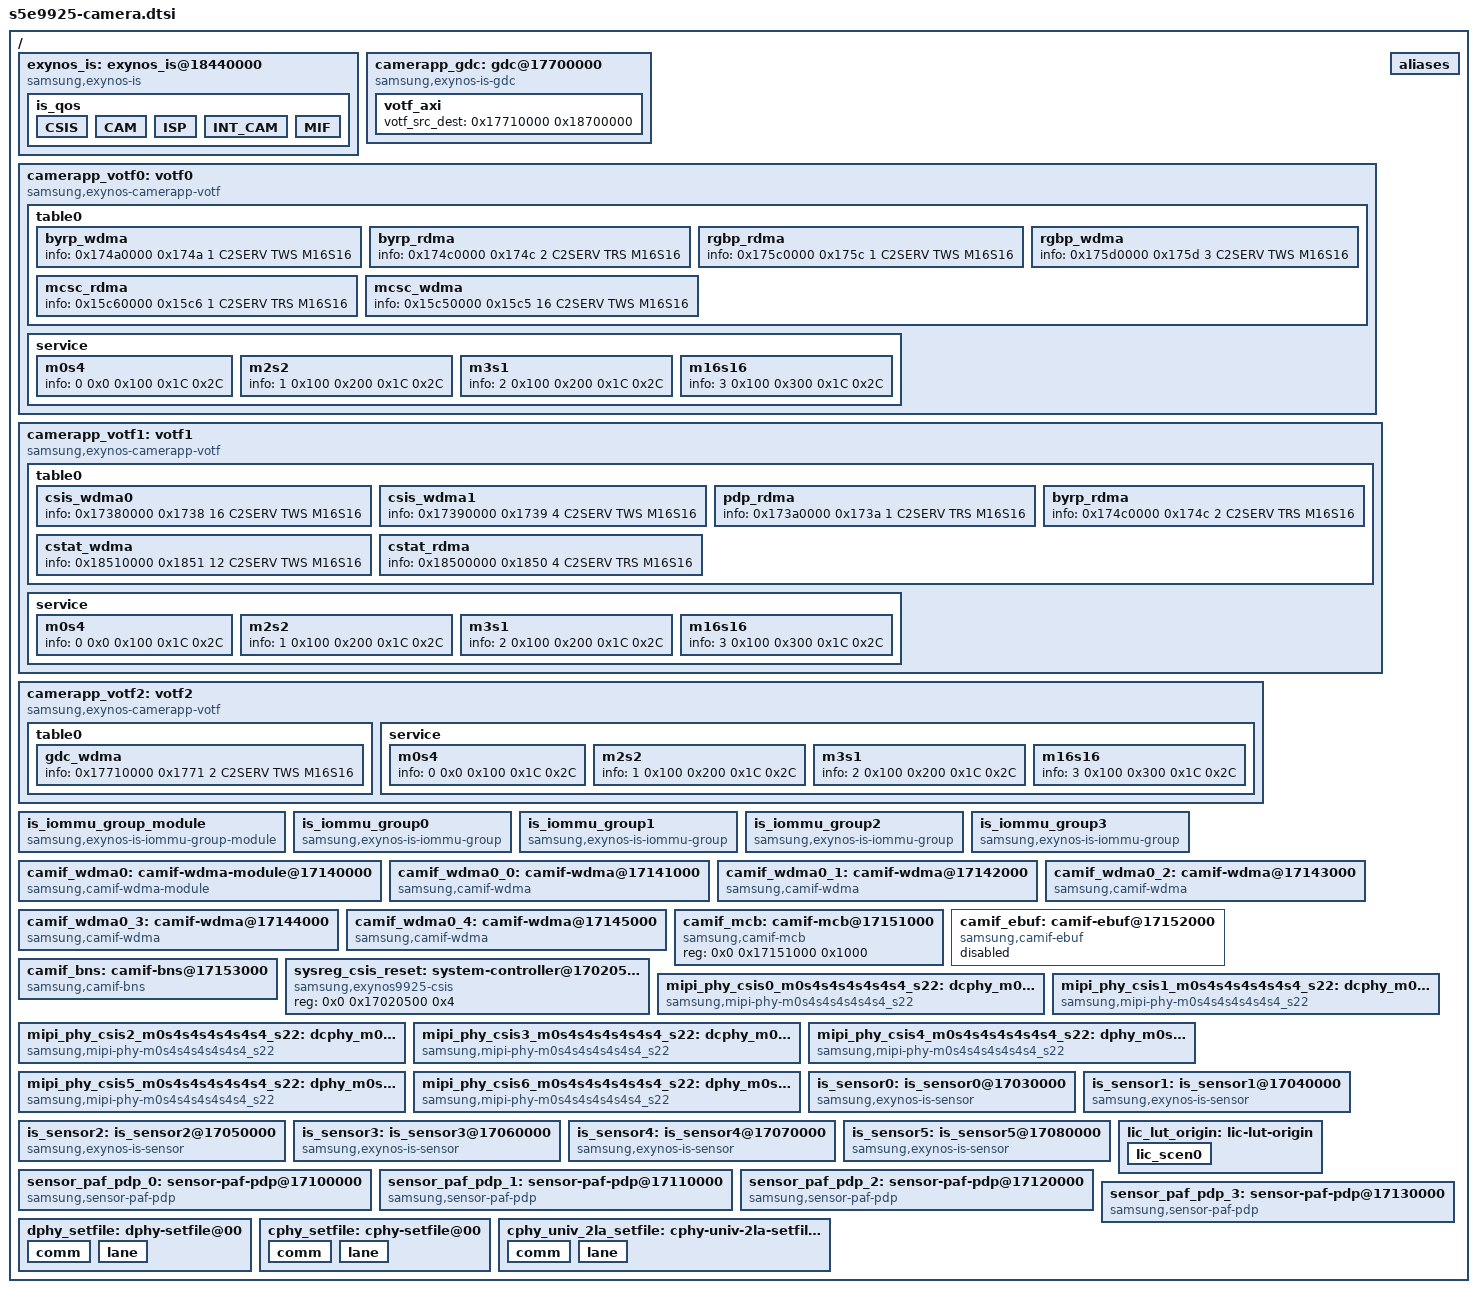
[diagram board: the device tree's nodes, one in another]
/*
 * SAMSUNG EXYNOS9925 SoC camera device tree source
 *
 * Copyright (c) 2021 Samsung Electronics Co., Ltd.
 *		http://www.samsung.com
 *
 * SAMSUNG EXYNOS9925 SoC camera device nodes are listed in this file.
 * EXYNOS9925 based board files can include this file and provide
 * values for board specfic bindings.
 *
 * This program is free software; you can redistribute it and/or modify
 * it under the terms of the GNU General Public License version 2 as
 * published by the Free Software Foundation.
 */

#include <dt-bindings/clock/s5e9925.h>
#include <dt-bindings/interrupt-controller/arm-gic.h>
#include <dt-bindings/interrupt-controller/s5e9925.h>
#include <dt-bindings/camera/exynos_is_dt.h>
#include <dt-bindings/camera/votf.h>
#include "s5e9925-pinctrl.dtsi"

/ {
	exynos_is: exynos_is@18440000 {
		compatible = "samsung,exynos-is";
		reg = <0x0 0x17140000 0x10000>, /* CSIS_WDMA */
		    <0x0 0x17100000 0x10000>, /* PDP_CORE0 */
		    <0x0 0x17110000 0x10000>, /* PDP_CORE1 */
		    <0x0 0x17120000 0x10000>, /* PDP_CORE2 */
		    <0x0 0x17130000 0x10000>, /* PDP_CORE3 */
		    <0x0 0x18440000 0x10000>, /* CSTAT0 */
		    <0x0 0x18450000 0x10000>, /* CSTAT1 */
		    <0x0 0x18460000 0x10000>, /* CSTAT2 */
		    <0x0 0x18470000 0x10000>, /* CSTAT3 */
		    <0x0 0x17140000 0x10000>, /* ZSL/STRIP DMA  */
		    <0x0 0x17630000 0x10000>, /* LME */
		    <0x0 0x17480000 0x10000>, /* BYRP */
		    <0x0 0x175B0000 0x10000>, /* RGBP */
		    <0x0 0x15E00000 0x10000>, /* MCFP */
		    <0x0 0x18040000 0x10000>, /* YUVP */
		    <0x0 0x15C40000 0x10000>; /* MCSC */
		interrupts = <0 INTREQ__CSTAT_CH0_0 IRQ_TYPE_LEVEL_HIGH>, /*CSTAT0_0 */
			<0 INTREQ__CSTAT_CH0_1 IRQ_TYPE_LEVEL_HIGH>,      /* CSTAT0_1 */
			<0 INTREQ__CSTAT_CH1_0 IRQ_TYPE_LEVEL_HIGH>,      /* CSTAT1_0 */
			<0 INTREQ__CSTAT_CH1_1 IRQ_TYPE_LEVEL_HIGH>,      /* CSTAT1_1 */
			<0 INTREQ__CSTAT_CH2_0 IRQ_TYPE_LEVEL_HIGH>,      /* CSTAT2_0 */
			<0 INTREQ__CSTAT_CH2_1 IRQ_TYPE_LEVEL_HIGH>,      /* CSTAT2_1 */
			<0 INTREQ__CSTAT_CH3_0 IRQ_TYPE_LEVEL_HIGH>,      /* CSTAT3_0 */
			<0 INTREQ__CSTAT_CH3_1 IRQ_TYPE_LEVEL_HIGH>,      /* CSTAT3_1 */
			<0 INTREQ__LME_O_INT0 IRQ_TYPE_LEVEL_HIGH>,       /* LME_0 */
			<0 INTREQ__BYRP_0 IRQ_TYPE_LEVEL_HIGH>,           /* BYRP_0 */
			<0 INTREQ__BYRP_1 IRQ_TYPE_LEVEL_HIGH>,           /* BYRP_1 */
			<0 INTREQ__RGBP_0 IRQ_TYPE_LEVEL_HIGH>,           /* RGBP_0 */
			<0 INTREQ__RGBP_1 IRQ_TYPE_LEVEL_HIGH>,           /* RGBP_1 */
			<0 INTREQ__MCFP_INTREQ_0 IRQ_TYPE_LEVEL_HIGH>,    /* MCFP_0 */
			<0 INTREQ__MCFP_INTREQ_1 IRQ_TYPE_LEVEL_HIGH>,    /* MCFP_1 */
			<0 INTREQ__YUVP_0 IRQ_TYPE_LEVEL_HIGH>,           /* YUVP_0 */
			<0 INTREQ__YUVP_1 IRQ_TYPE_LEVEL_HIGH>,           /* YUVP_1 */
			<0 INTREQ__MCSC_INTREQ_0 IRQ_TYPE_LEVEL_HIGH>,    /* MCSC_0 */
			<0 INTREQ__MCSC_INTREQ_1 IRQ_TYPE_LEVEL_HIGH>;    /* MCSC_1 */
		pinctrl-names = "default","release";
		pinctrl-0 = <>;
		pinctrl-1 = <>;
		clocks = <&clock GATE_DFTMUX_CMU_QCH_CIS_CLK0>,
		      <&clock GATE_DFTMUX_CMU_QCH_CIS_CLK1>,
		      <&clock GATE_DFTMUX_CMU_QCH_CIS_CLK2>,
		      <&clock GATE_DFTMUX_CMU_QCH_CIS_CLK3>,
		      <&clock GATE_DFTMUX_CMU_QCH_CIS_CLK4>,
		      <&clock GATE_DFTMUX_CMU_QCH_CIS_CLK5>,
		      <&clock GATE_DFTMUX_CMU_QCH_CIS_CLK6>,
		      <&clock GATE_DFTMUX_CMU_QCH_CIS_CLK7>,

		      <&clock DOUT_DIV_CLKCMU_CIS_CLK0>,
		      <&clock DOUT_DIV_CLKCMU_CIS_CLK1>,
		      <&clock DOUT_DIV_CLKCMU_CIS_CLK2>,
		      <&clock DOUT_DIV_CLKCMU_CIS_CLK3>,
		      <&clock DOUT_DIV_CLKCMU_CIS_CLK4>,
		      <&clock DOUT_DIV_CLKCMU_CIS_CLK5>,
		      <&clock DOUT_DIV_CLKCMU_CIS_CLK6>,
		      <&clock DOUT_DIV_CLKCMU_CIS_CLK7>,

		      <&clock GATE_CSIS_PDP_QCH_DMA>,

		      <&clock GATE_MIPI_PHY_LINK_WRAP_QCH_CSIS0>,
		      <&clock GATE_MIPI_PHY_LINK_WRAP_QCH_CSIS1>,
		      <&clock GATE_MIPI_PHY_LINK_WRAP_QCH_CSIS2>,
		      <&clock GATE_MIPI_PHY_LINK_WRAP_QCH_CSIS3>,
		      <&clock GATE_MIPI_PHY_LINK_WRAP_QCH_CSIS4>,
		      <&clock GATE_MIPI_PHY_LINK_WRAP_QCH_CSIS5>,
		      <&clock GATE_MIPI_PHY_LINK_WRAP_QCH_CSIS6>,

		      <&clock GATE_CSIS_PDP_QCH_PDP>,
		      <&clock GATE_LH_AST_SI_OTF0_CSISCSTAT_QCH>,
		      <&clock GATE_LH_AST_SI_OTF1_CSISCSTAT_QCH>,
		      <&clock GATE_LH_AST_SI_OTF2_CSISCSTAT_QCH>,
		      <&clock GATE_LH_AST_SI_OTF3_CSISCSTAT_QCH>,
		      <&clock GATE_LME_QCH_0>,
		      <&clock GATE_MCFP_QCH>,
		      <&clock GATE_YUVP_QCH>,
		      <&clock GATE_MCSC_QCH>;
		      /* <&clock GATE_GDC_QCH>; */
		clock-names = "GATE_DFTMUX_CMU_QCH_CIS_CLK0",
			"GATE_DFTMUX_CMU_QCH_CIS_CLK1",
			"GATE_DFTMUX_CMU_QCH_CIS_CLK2",
			"GATE_DFTMUX_CMU_QCH_CIS_CLK3",
			"GATE_DFTMUX_CMU_QCH_CIS_CLK4",
			"GATE_DFTMUX_CMU_QCH_CIS_CLK5",
			"GATE_DFTMUX_CMU_QCH_CIS_CLK6",
			"GATE_DFTMUX_CMU_QCH_CIS_CLK7",

			"DOUT_DIV_CLKCMU_CIS_CLK0",
			"DOUT_DIV_CLKCMU_CIS_CLK1",
			"DOUT_DIV_CLKCMU_CIS_CLK2",
			"DOUT_DIV_CLKCMU_CIS_CLK3",
			"DOUT_DIV_CLKCMU_CIS_CLK4",
			"DOUT_DIV_CLKCMU_CIS_CLK5",
			"DOUT_DIV_CLKCMU_CIS_CLK6",
			"DOUT_DIV_CLKCMU_CIS_CLK7",

			"GATE_CSIS_PDP_QCH_DMA",

			"GATE_MIPI_PHY_LINK_WRAP_QCH_CSIS0",
			"GATE_MIPI_PHY_LINK_WRAP_QCH_CSIS1",
			"GATE_MIPI_PHY_LINK_WRAP_QCH_CSIS2",
			"GATE_MIPI_PHY_LINK_WRAP_QCH_CSIS3",
			"GATE_MIPI_PHY_LINK_WRAP_QCH_CSIS4",
			"GATE_MIPI_PHY_LINK_WRAP_QCH_CSIS5",
			"GATE_MIPI_PHY_LINK_WRAP_QCH_CSIS6",

			"GATE_CSIS_PDP_QCH_PDP",
			"GATE_LH_AST_SI_OTF0_CSISCSTAT_QCH",
			"GATE_LH_AST_SI_OTF1_CSISCSTAT_QCH",
			"GATE_LH_AST_SI_OTF2_CSISCSTAT_QCH",
			"GATE_LH_AST_SI_OTF3_CSISCSTAT_QCH",
			"GATE_LME_QCH_0",
			"GATE_MCFP_QCH",
			"GATE_YUVP_QCH",
			"GATE_MCSC_QCH";
			/* "GATE_GDC_QCH"; */
		status = "ok";
		iommus = <&sysmmu_d0_csis>,
		       <&sysmmu_d1_csis>,
		       <&sysmmu_d2_csis>,
		       <&sysmmu_d_cstat>,
		       <&sysmmu_d0_brp>;
		samsung,iommu-group = <&iommu_group_is>;
		#cooling-cells = <2>; /* min followed by max */
		ewf-index = <EWF_GRP_CAM>;
		list-scen-bts = "camera_default", "camera_heavy";
		num_of_3aa = <4>;
		num_of_lme = <1>;
		num_of_isp = <0>;
		num_of_byrp = <1>;
		num_of_rgbp = <1>;
		num_of_mcsc = <1>;
		num_of_vra = <0>;
		num_of_clh = <0>;
		num_of_ypp = <1>;
		num_of_mcfp = <1>;

		memory-region = <&camera_bin>;
		samsung,tzmp;

		phy_ldos = "AVDD_CSI_0P85", "AVDD_CSI_1P2";

		is_qos {
			CSIS { /* CSIS, CSTAT */
				typ = <IS_DVFS_CSIS>;
				lev = <0      1      2      3      4      5      6      7      8>;
				frq = <745    663    533    468    400    332    267    166    50>;
				qos = <745000 663000 533000 468000 400000 332000 267000 166000 50000>;
			};

			CAM { /* BYRP, RGBP, MCSC */
				typ = <IS_DVFS_CAM>;
				lev = <0      1      2      3      4      5      6      7      8>;
				frq = <745    663    533    468    400    332    234    166    50>;
				qos = <745000 663000 533000 468000 400000 332000 234000 166000 50000>;
			};

			ISP { /* MCFP, YUVP */
				typ = <IS_DVFS_ISP>;
				lev = <0      1      2      3      4      5      6      7      8>;
				frq = <745    663    533    468    400    332    234    166    50>;
				qos = <745000 663000 533000 468000 400000 332000 234000 166000 50000>;
			};

			INT_CAM { /* LME, GDC */
				typ = <IS_DVFS_INT_CAM>;
				lev = <0      1      2      3      4      5      6      7      8>;
				frq = <745    663    533    468    400    332    234    166    50>;
				qos = <745000 663000 533000 468000 400000 332000 234000 166000 50000>;
			};

			MIF {
				typ = <IS_DVFS_MIF>;
				lev = <0       1       2       3       4       5       6       7       8       9      10     11     12>;
				frq = <3172    2730    2535    2288    2028    1715    1539    1352    1014    845    676    546    421>;
				qos = <3172000 2730000 2535000 2288000 2028000 1715500 1539000 1352000 1014000 845000 676000 546000 421000>;
			};
		};
	};

	camerapp_gdc: gdc@17700000 {
		compatible = "samsung,exynos-is-gdc";
		reg = <0x0 0x17700000 0x10000>; /* GDC */
		interrupts = <0 INTREQ__GDC_IRQ_0 IRQ_TYPE_LEVEL_HIGH>, /* GDC_0 */
			   <0 INTREQ__GDC_IRQ_1 IRQ_TYPE_LEVEL_HIGH>;    /* GDC_1 */
		pinctrl-names = "default","release";
		pinctrl-0 = <>;
		pinctrl-1 = <>;
		clocks = <&clock GATE_LME_QCH_0>;
		clock-names = "gate";
		status = "okay";
		iommus = <&sysmmu_d_lme>;
		samsung,iommu-group = <&iommu_group_is_1>;
		#cooling-cells = <2>; /* min followed by max */
		dma-coherent;

		votf_axi {
			votf_src_dest = <0x17710000 0x18700000>;
		};
	};

	camerapp_votf0: votf0 {
		compatible = "samsung,exynos-camerapp-votf";
		id = <0>;
		iommus = <&sysmmu_d0_mcsc>,
			<&sysmmu_d1_mcsc>,
			<&sysmmu_d2_mcsc>,
			<&sysmmu_d3_mcsc>,
			<&sysmmu_d4_mcsc>,
			<&sysmmu_d1_brp>,
			<&sysmmu_d2_brp>;
		samsung,iommu-group = <&iommu_group_is_2>;
		status = "okay";
		use_axi;

		table0{
			/* base address, ip num, id cnt, C2SERV/C2AGENT, TWS/TRS, module type */
			byrp_wdma	{ info = <0x174a0000 0x174a  1 C2SERV TWS M16S16>; };
			byrp_rdma	{ info = <0x174c0000 0x174c  2 C2SERV TRS M16S16>; };
			rgbp_rdma	{ info = <0x175c0000 0x175c  1 C2SERV TWS M16S16>; };
			rgbp_wdma	{ info = <0x175d0000 0x175d  3 C2SERV TWS M16S16>; };
			mcsc_rdma	{ info = <0x15c60000 0x15c6  1 C2SERV TRS M16S16>; };
			mcsc_wdma	{ info = <0x15c50000 0x15c5 16 C2SERV TWS M16S16>; };
		};

		service {
			/* num, tws addr, trs addr, tws gap, trs gap */
			m0s4	{ info = <0   0x0 0x100 0x1C 0x2C>; };
			m2s2	{ info = <1 0x100 0x200 0x1C 0x2C>; };
			m3s1	{ info = <2 0x100 0x200 0x1C 0x2C>; };
			m16s16	{ info = <3 0x100 0x300 0x1C 0x2C>; };
		};
	};

	camerapp_votf1: votf1 {
		compatible = "samsung,exynos-camerapp-votf";
		id = <1>;
		iommus = <&sysmmu_d0_csis>,
		       <&sysmmu_d1_csis>,
		       <&sysmmu_d2_csis>,
		       <&sysmmu_d_cstat>,
		       <&sysmmu_d0_brp>;
		samsung,iommu-group = <&iommu_group_is>;
		status = "okay";
		use_axi;

		table0{
			/* base address, ip num, id cnt, C2SERV/C2AGENT, TWS/TRS, module type */
			csis_wdma0	{ info = <0x17380000 0x1738 16 C2SERV TWS M16S16>; };
			csis_wdma1	{ info = <0x17390000 0x1739  4 C2SERV TWS M16S16>; };
			pdp_rdma	{ info = <0x173a0000 0x173a  1 C2SERV TRS M16S16>; };
			byrp_rdma	{ info = <0x174c0000 0x174c  2 C2SERV TRS M16S16>; };
			cstat_wdma	{ info = <0x18510000 0x1851 12 C2SERV TWS M16S16>; };
			cstat_rdma	{ info = <0x18500000 0x1850  4 C2SERV TRS M16S16>; };
		};

		service {
			/* num, tws addr, trs addr, tws gap, trs gap */
			m0s4	{ info = <0   0x0 0x100 0x1C 0x2C>; };
			m2s2	{ info = <1 0x100 0x200 0x1C 0x2C>; };
			m3s1	{ info = <2 0x100 0x200 0x1C 0x2C>; };
			m16s16	{ info = <3 0x100 0x300 0x1C 0x2C>; };
		};
	};

	camerapp_votf2: votf2 {
		compatible = "samsung,exynos-camerapp-votf";
		id = <2>;
		iommus = <&sysmmu_d_lme>;
		samsung,iommu-group = <&iommu_group_is_1>;
		status = "okay";
		use_axi;

		table0{
			/* base address, ip num, id cnt, C2SERV/C2AGENT, TWS/TRS, module type */
			gdc_wdma   { info = <0x17710000 0x1771 2 C2SERV TWS M16S16>; };
		};

		service {
			/* num, tws addr, trs addr, tws gap, trs gap */
			m0s4	{ info = <0   0x0 0x100 0x1C 0x2C>; };
			m2s2	{ info = <1 0x100 0x200 0x1C 0x2C>; };
			m3s1	{ info = <2 0x100 0x200 0x1C 0x2C>; };
			m16s16	{ info = <3 0x100 0x300 0x1C 0x2C>; };
		};
	};

	is_iommu_group_module: is_iommu_group_module {
		compatible = "samsung,exynos-is-iommu-group-module";
		groups = <&is_iommu_group0>,
			<&is_iommu_group1>,
			<&is_iommu_group2>,
			<&is_iommu_group3>;
	};

	aliases {
		iommu-group-module0 = &is_iommu_group_module;
	};

	is_iommu_group0: is_iommu_group0 {
		compatible = "samsung,exynos-is-iommu-group";
		iommus = <&sysmmu_d0_csis>,
		       <&sysmmu_d1_csis>,
		       <&sysmmu_d2_csis>,
		       <&sysmmu_d_cstat>,
		       <&sysmmu_d0_brp>;
		samsung,iommu-group = <&iommu_group_is>;
	};

	is_iommu_group1: is_iommu_group1 {
		compatible = "samsung,exynos-is-iommu-group";
		iommus = <&sysmmu_d_lme>;
		samsung,iommu-group = <&iommu_group_is_1>;
	};

	is_iommu_group2: is_iommu_group2 {
		compatible = "samsung,exynos-is-iommu-group";
		iommus = <&sysmmu_d0_mcsc>,
		       <&sysmmu_d1_mcsc>,
		       <&sysmmu_d2_mcsc>,
		       <&sysmmu_d3_mcsc>,
		       <&sysmmu_d4_mcsc>,
		       <&sysmmu_d1_brp>,
		       <&sysmmu_d2_brp>;
		samsung,iommu-group = <&iommu_group_is_2>;
	};

	is_iommu_group3: is_iommu_group3 {
		compatible = "samsung,exynos-is-iommu-group";
		iommus = <&sysmmu_d0_yuvp>,
		       <&sysmmu_d1_yuvp>;
		samsung,iommu-group = <&iommu_group_is_3>;
	};

	aliases {
		iommu-group0 = &is_iommu_group0;
		iommu-group1 = &is_iommu_group1;
		iommu-group2 = &is_iommu_group2;
		iommu-group3 = &is_iommu_group3;
	};

	camif_wdma0: camif-wdma-module@17140000 {
		compatible = "samsung,camif-wdma-module";
		reg = <0x0 0x17140000 0x300>;
		reg-names = "ctl";
		channels = <&camif_wdma0_0>,
			<&camif_wdma0_1>,
			<&camif_wdma0_2>,
			<&camif_wdma0_3>,
			<&camif_wdma0_4>;
		samsung,quirks = "has test pattern gen";
	};

	aliases {
		wdma-module0 = &camif_wdma0;
	};

	camif_wdma0_0: camif-wdma@17141000 {
		compatible = "samsung,camif-wdma";
		reg = <0x0 0x17020520 0x4>,	/* input MUX */
			<0x0 0x17141400 0x100>,	/* CTL */
			<0x0 0x17141000 0x100>,	/* VC0 */
			<0x0 0x17141100 0x100>,	/* VC1 */
			<0x0 0x17141200 0x100>,	/* VC2 */
			<0x0 0x17141300 0x100>;	/* VC3 */
		reg-names = "mux", "ctl", "vc0", "vc1", "vc2", "vc3";
		interrupts = <GIC_SPI INTREQ__CSIS_DMA0 IRQ_TYPE_LEVEL_HIGH>;
		interrupt-names = "dma";
		module = <&camif_wdma0>;
	};

	camif_wdma0_1: camif-wdma@17142000 {
		compatible = "samsung,camif-wdma";
		reg = <0x0 0x17020524 0x4>,	/* input MUX */
			<0x0 0x17142400 0x100>,	/* CTL */
			<0x0 0x17142000 0x100>,	/* VC0 */
			<0x0 0x17142100 0x100>,	/* VC1 */
			<0x0 0x17142200 0x100>,	/* VC2 */
			<0x0 0x17142300 0x100>;	/* VC3 */
		reg-names = "mux", "ctl", "vc0", "vc1", "vc2", "vc3";
		interrupts = <GIC_SPI INTREQ__CSIS_DMA1 IRQ_TYPE_LEVEL_HIGH>;
		interrupt-names = "dma";
		module = <&camif_wdma0>;
	};

	camif_wdma0_2: camif-wdma@17143000 {
		compatible = "samsung,camif-wdma";
		reg = <0x0 0x17020528 0x4>,	/* input MUX */
			<0x0 0x17143400 0x100>,	/* CTL */
			<0x0 0x17143000 0x100>,	/* VC0 */
			<0x0 0x17143100 0x100>,	/* VC1 */
			<0x0 0x17143200 0x100>,	/* VC2 */
			<0x0 0x17143300 0x100>;	/* VC3 */
		reg-names = "mux", "ctl", "vc0", "vc1", "vc2", "vc3";
		interrupts = <GIC_SPI INTREQ__CSIS_DMA2 IRQ_TYPE_LEVEL_HIGH>;
		interrupt-names = "dma";
		module = <&camif_wdma0>;
	};

	camif_wdma0_3: camif-wdma@17144000 {
		compatible = "samsung,camif-wdma";
		reg = <0x0 0x1702052C 0x4>,	/* input MUX */
			<0x0 0x17144400 0x100>,	/* CTL */
			<0x0 0x17144000 0x100>,	/* VC0 */
			<0x0 0x17144100 0x100>,	/* VC1 */
			<0x0 0x17144200 0x100>,	/* VC2 */
			<0x0 0x17144300 0x100>;	/* VC3 */
		reg-names = "mux", "ctl", "vc0", "vc1", "vc2", "vc3";
		interrupts = <GIC_SPI INTREQ__CSIS_DMA3 IRQ_TYPE_LEVEL_HIGH>;
		interrupt-names = "dma";
		module = <&camif_wdma0>;
	};

	camif_wdma0_4: camif-wdma@17145000 {
		compatible = "samsung,camif-wdma";
		reg = <0x0 0x17020490 0x4>,	/* input MUX */
			<0x0 0x17145400 0x100>,	/* CTL */
			<0x0 0x17145000 0x100>,	/* VC0 */
			<0x0 0x17145100 0x100>,	/* VC1 */
			<0x0 0x17145200 0x100>,	/* VC2 */
			<0x0 0x17145300 0x100>;	/* VC3 */
		reg-names = "mux", "ctl", "vc0", "vc1", "vc2", "vc3";
		interrupts = <GIC_SPI INTREQ__CSIS_DMA4 IRQ_TYPE_LEVEL_HIGH>;
		interrupt-names = "dma";
		module = <&camif_wdma0>;
	};

	aliases {
		wdma0 = &camif_wdma0_0;
		wdma1 = &camif_wdma0_1;
		wdma2 = &camif_wdma0_2;
		wdma3 = &camif_wdma0_3;
		wdma4 = &camif_wdma0_4;
	};

	camif_mcb: camif-mcb@17151000 {
		compatible = "samsung,camif-mcb";
		reg = <0x0 0x17151000 0x1000>;
	};

	camif_ebuf: camif-ebuf@17152000 {
		compatible = "samsung,camif-ebuf";
		reg = <0x0 0x17152000 0x1000>;
		interrupts = <0 INTREQ__SENSOR_ABORT IRQ_TYPE_LEVEL_HIGH>;
		num_of_ebuf = <4>;
		status = "disabled";
	};

	camif_bns: camif-bns@17153000 {
		compatible = "samsung,camif-bns";
		reg = <0x0 0x17153000 0x100>,
		    <0x0 0x17020494 0x4>; /* CSIS_PDP_BNS_MUX */
		reg-names = "ctl", "mux";

		mux = <0 1 2 3>; /* BNS in/out channel selection */
		dma_mux = <0x24>; /* DMA mux for BNS out */
	};

	sysreg_csis_reset: system-controller@17020500 {
		compatible = "samsung,exynos9925-csis", "syscon";
		reg = <0x0 0x17020500 0x4>;
	};

	mipi_phy_csis0_m0s4s4s4s4s4s4_s22: dcphy_m0s4s4s4s4s4s4_s22_csi0@170F1300 {
		/* DPHY 6.5 Gbps 4lane */
		/* CPHY 6.5 Gbps 3lane */
		compatible = "samsung,mipi-phy-m0s4s4s4s4s4s4_s22";
		samsung,pmu-syscon = <&pmu_system_controller>;
		power-gating = <0xA88>; /* PMU address offset */
		samsung,reset-sysreg = <&sysreg_csis_reset>;
		reset = <0>; /* reset bit */
		reg = <0x0 0x170F1300 0x500>;
		owner = <1>; /* 0: DSI,  1: CSI */
		#phy-cells = <1>;
	};

	mipi_phy_csis1_m0s4s4s4s4s4s4_s22: dcphy_m0s4s4s4s4s4s4_s22_csi1@170F1B00 {
		/* DPHY 6.5 Gbps 4lane */
		/* CPHY 6.5 Gbps 3lane */
		compatible = "samsung,mipi-phy-m0s4s4s4s4s4s4_s22";
		samsung,pmu-syscon = <&pmu_system_controller>;
		power-gating = <0xA8C>; /* PMU address offset */
		samsung,reset-sysreg = <&sysreg_csis_reset>;
		reset = <1>; /* reset bit */
		reg = <0x0 0x170F1B00 0x500>;
		owner = <1>; /* 0: DSI,  1: CSI */
		#phy-cells = <1>;
	};

	mipi_phy_csis2_m0s4s4s4s4s4s4_s22: dcphy_m0s4s4s4s4s4s4_s22_csi2@170F2300 {
		/* DPHY 6.5 Gbps 4lane */
		/* CPHY 6.5 Gbps 3lane */
		compatible = "samsung,mipi-phy-m0s4s4s4s4s4s4_s22";
		samsung,pmu-syscon = <&pmu_system_controller>;
		power-gating = <0xA90>; /* PMU address offset */
		samsung,reset-sysreg = <&sysreg_csis_reset>;
		reset = <2>; /* reset bit */
		reg = <0x0 0x170F2300 0x500>;
		owner = <1>; /* 0: DSI,  1: CSI */
		#phy-cells = <1>;
	};

	mipi_phy_csis3_m0s4s4s4s4s4s4_s22: dcphy_m0s4s4s4s4s4s4_s22_csi3@170F2B00 {
		/* DPHY 6.5 Gbps 4lane */
		/* CPHY 6.5 Gbps 3lane */
		compatible = "samsung,mipi-phy-m0s4s4s4s4s4s4_s22";
		samsung,pmu-syscon = <&pmu_system_controller>;
		power-gating = <0xA94>; /* PMU address offset */
		samsung,reset-sysreg = <&sysreg_csis_reset>;
		reset = <3>; /* reset bit */
		reg = <0x0 0x170F2B00 0x500>;
		owner = <1>; /* 0: DSI,  1: CSI */
		#phy-cells = <1>;
	};

	mipi_phy_csis4_m0s4s4s4s4s4s4_s22: dphy_m0s4s4s4s4s4s4_s22_csi4@170F3300 {
		/* DPHY 6.5 Gbps 4lane */
		/* CPHY 6.5 Gbps 3lane */
		compatible = "samsung,mipi-phy-m0s4s4s4s4s4s4_s22";
		samsung,pmu-syscon = <&pmu_system_controller>;
		power-gating = <0xA98>; /* PMU address offset */
		samsung,reset-sysreg = <&sysreg_csis_reset>;
		reset = <7>; /* reset bit */
		reg = <0x0 0x170F3300 0x500>;
		owner = <1>; /* 0: DSI,  1: CSI */
		#phy-cells = <1>;
	};

	mipi_phy_csis5_m0s4s4s4s4s4s4_s22: dphy_m0s4s4s4s4s4s4_s22_csi5@170F3B00 {
		/* DPHY 6.5 Gbps 4lane */
		compatible = "samsung,mipi-phy-m0s4s4s4s4s4s4_s22";
		samsung,pmu-syscon = <&pmu_system_controller>;
		power-gating = <0xA9C>; /* PMU address offset */
		samsung,reset-sysreg = <&sysreg_csis_reset>;
		reset = <4>; /* reset bit */
		reg = <0x0 0x170F3B00 0x500>;
		owner = <1>; /* 0: DSI,  1: CSI */
		#phy-cells = <1>;
	};

	mipi_phy_csis6_m0s4s4s4s4s4s4_s22: dphy_m0s4s4s4s4s4s4_s22_csi5@170F3A00 {
		/* DPHY 6.5 Gbps 2lane */
		compatible = "samsung,mipi-phy-m0s4s4s4s4s4s4_s22";
		samsung,pmu-syscon = <&pmu_system_controller>;
		power-gating = <0xAA0>; /* PMU address offset */
		samsung,reset-sysreg = <&sysreg_csis_reset>;
		reset = <5>; /* reset bit */
		reg = <0x0 0x170F3A00 0x100>;
		owner = <1>; /* 0: DSI,  1: CSI */
		#phy-cells = <1>;
	};

	is_sensor0: is_sensor0@17030000 {
		/* CSIS0 */
		compatible = "samsung,exynos-is-sensor";
		#address-cells = <1>;
		#size-cells = <1>;
		reg = <0x0 0x17030000 0x1000>, /* MIPI-CSI0 */
			<0x0 0x170F0000 0x10000>, /* PHY: M0S4S4S4S4S4S2 */
			<0x0 0x17150050 0x10>; /* CSIS_FRO */
		reg-names = "csi", "phy", "fro";
		interrupts = <0 INTREQ__CSIS0 IRQ_TYPE_LEVEL_HIGH>; /*MIPI-CSI0 */
		interrupt-names = "csi";
		phys = <&mipi_phy_csis0_m0s4s4s4s4s4s4_s22 0>;
		phy-names = "csis_dphy";
		phy_setfile = <&dphy_setfile>;
		iommus = <&sysmmu_d0_csis>, <&sysmmu_d1_csis>;
		samsung,iommu-group = <&iommu_group_is>;
	};

	is_sensor1: is_sensor1@17040000 {
		/* CSIS1 */
		compatible = "samsung,exynos-is-sensor";
		#address-cells = <1>;
		#size-cells = <1>;
		reg = <0x0 0x17040000 0x1000>, /* MIPI-CSI1 */
			<0x0 0x170F0000 0x10000>, /* PHY: M0S4S4S4S4S4S2 */
			<0x0 0x17150050 0x10>; /* CSIS_FRO */
		reg-names = "csi", "phy", "fro";
		interrupts = <0 INTREQ__CSIS1 IRQ_TYPE_LEVEL_HIGH>; /* MIPI-CSI1 */
		interrupt-names = "csi";
		phys = <&mipi_phy_csis1_m0s4s4s4s4s4s4_s22 0>;
		phy-names = "csis_dphy";
		phy_setfile = <&dphy_setfile>;
		iommus = <&sysmmu_d0_csis>, <&sysmmu_d1_csis>;
		samsung,iommu-group = <&iommu_group_is>;
		samsung,tzmp;
	};

	is_sensor2: is_sensor2@17050000 {
		/* CSIS2 */
		compatible = "samsung,exynos-is-sensor";
		#address-cells = <1>;
		#size-cells = <1>;
		reg = <0x0 0x17050000 0x1000>, /* MIPI-CSI2 */
			<0x0 0x170F0000 0x10000>, /* PHY: M0S4S4S4S4S4S2 */
			<0x0 0x17150050 0x10>; /* CSIS_FRO */
		reg-names = "csi", "phy", "fro";
		interrupts = <0 INTREQ__CSIS2 IRQ_TYPE_LEVEL_HIGH>; /* MIPI-CSI2 */
		interrupt-names = "csi";
		phys = <&mipi_phy_csis2_m0s4s4s4s4s4s4_s22 0>;
		phy-names = "csis_dphy";
		phy_setfile = <&dphy_setfile>;
		iommus = <&sysmmu_d0_csis>, <&sysmmu_d1_csis>;
		samsung,iommu-group = <&iommu_group_is>;
	};

	is_sensor3: is_sensor3@17060000 {
		/* CSIS3 */
		compatible = "samsung,exynos-is-sensor";
		#address-cells = <1>;
		#size-cells = <1>;
		reg = <0x0 0x17060000 0x1000>, /* MIPI-CSI3 */
			<0x0 0x170F0000 0x10000>, /* PHY: M0S4S4S4S4S4S2 */
			<0x0 0x17150050 0x10>; /* CSIS_FRO */
		reg-names = "csi", "phy", "fro";
		interrupts = <0 INTREQ__CSIS3 IRQ_TYPE_LEVEL_HIGH>; /* MIPI-CSI3 */
		interrupt-names = "csi";
		phys = <&mipi_phy_csis3_m0s4s4s4s4s4s4_s22 0>;
		phy-names = "csis_dphy";
		phy_setfile = <&dphy_setfile>;
		iommus = <&sysmmu_d0_csis>, <&sysmmu_d1_csis>;
		samsung,iommu-group = <&iommu_group_is>;
	};

	is_sensor4: is_sensor4@17070000 {
		/* CSIS4 */
		compatible = "samsung,exynos-is-sensor";
		#address-cells = <1>;
		#size-cells = <1>;
		reg = <0x0 0x17070000 0x1000>, /* MIPI-CSI4 */
			<0x0 0x170F0000 0x10000>, /* PHY: M0S4S4S4S4S4S2 */
			<0x0 0x17150050 0x10>; /* CSIS_FRO */
		reg-names = "csi", "phy", "fro";
		interrupts = <0 INTREQ__CSIS4 IRQ_TYPE_LEVEL_HIGH>; /* MIPI-CSI4 */
		interrupt-names = "csi";
		phys = <&mipi_phy_csis4_m0s4s4s4s4s4s4_s22 0>;
		phy-names = "csis_dphy";
		phy_setfile = <&dphy_setfile>;
		iommus = <&sysmmu_d0_csis>, <&sysmmu_d1_csis>;
		samsung,iommu-group = <&iommu_group_is>;
	};

	is_sensor5: is_sensor5@17080000 {
		/* CSIS5 */
		compatible = "samsung,exynos-is-sensor";
		#address-cells = <1>;
		#size-cells = <1>;
		reg = <0x0 0x17080000 0x1000>, /* MIPI-CSI5 */
			<0x0 0x170F0000 0x10000>, /* PHY: M0S4S4S4S4S4S2 */
			<0x0 0x17150050 0x10>; /* CSIS_FRO */
		reg-names = "csi", "phy", "fro";
		interrupts = <0 INTREQ__CSIS5 IRQ_TYPE_LEVEL_HIGH>; /* MIPI-CSI5 */
		interrupt-names = "csi";
		phys = <&mipi_phy_csis5_m0s4s4s4s4s4s4_s22 0>;
		phy-names = "csis_dphy";
		phy_setfile = <&dphy_setfile>;
		iommus = <&sysmmu_d0_csis>, <&sysmmu_d1_csis>;
		samsung,iommu-group = <&iommu_group_is>;
	};

	lic_lut_origin: lic-lut-origin {
		#define LIC_MODE_DYNAMIC	(0)
		#define LIC_MODE_STATIC		(1)
		#define LIC_PATH_OTF		(0)
		#define LIC_PATH_DMA		(1)

		lic_mode_default = <LIC_MODE_DYNAMIC>;
		lic_14bit = <0>;
		lic_dma_only = <0>; /* Use this when NOT using OTF input at all. */

		/*
		 * When DYNAMIC mode is selected, param means enable limitation for DMA path.
		 * Example:
		 * @ mode = <LIC_MODE_DYNAMIC>;
		 * @ param0 = <LIC_PATH_OTF>;
		 * @ param1 = <LIC_PATH_DMA>;
		 * @ param2 = <LIC_PATH_OTF>;
		 *
		 * When STATIC mode is selected, param means buffer size for each context.
		 * Example:
		 * @ mode = <LIC_MODE_STAIC>;
		 * @ param0 = <3584>;
		 * @ param1 = <3583>;
		 * @ param2 = <1>;
		 *
		 * The lic_scen0 is not abailable. If the index of LUT is "0", the selection is skipped.
		 */
		lic_scen0 { /* Reserved */
			mode = <0>;
			param0 = <0>;
			param1 = <0>;
			param2 = <0>;
		};
	};

	sensor_paf_pdp_0: sensor-paf-pdp@17100000 {
		/* PDP CORE0 */
		compatible = "samsung,sensor-paf-pdp";
		reg = <0x0 0x17100000 0x10000>, /* PDP CORE0 */
			<0x0 0x17100000 0x10000>, /* PDP CORE0: For common regiser */
			<0x0 0x17020510 0x4>, /* PDP input mux(CSIS_PDP_SC_CON0) in SYSREG */
			<0x0 0x17020430 0x4>, /* PDP input vc mux(CSIS_PDP_VC_CON0) in SYSREG */
			<0x0 0x17020530 0x4>; /* CSIS_PDP_SC_PDP_IN_EN in SYSREG */
		reg-names = "core", "common", "mux", "vc_mux", "en";
		interrupts = <0 INTREQ__PDP0 IRQ_TYPE_LEVEL_HIGH>,
			<0 INTREQ__PDP1 IRQ_TYPE_LEVEL_HIGH>;

		/*
		 * Select input CSIS link & VC
		 * <csi0 csi1 csi2 csi3 csi4 csi5 csi6>
		 */
		mux =  <0 1 2 3 4 5 6>;
		vc_mux = <0x2 0x2 0x2 0x2 0x2 0x2 0x2>, /* IMG: VC0, H_AF: VC2 */
		       <0x10003 0x10003 0x10003 0x10003 0x10003 0x10003 0x10003>; /* IMG: VC1, H_AF: VC3 */

		en =  <0 1 2 3 4 5 6>; /* bit postion: <csi0 csi1 csi2 csi3 csi4 csi5 csi6> */
		leader; /* have RDMA & create video node */
		lic_lut = <&lic_lut_origin>;
	};

	sensor_paf_pdp_1: sensor-paf-pdp@17110000 {
		/* PDP CORE1 */
		compatible = "samsung,sensor-paf-pdp";
		reg = <0x0 0x17110000 0x10000>, /* PDP CORE0 */
			<0x0 0x17100000 0x10000>, /* PDP CORE0: For common regiser */
			<0x0 0x17020514 0x4>, /* PDP input mux(CSIS_PDP_SC_CON0) in SYSREG */
			<0x0 0x17020434 0x4>, /* PDP input vc mux(CSIS_PDP_VC_CON0) in SYSREG */
			<0x0 0x17020534 0x4>; /* CSIS_PDP_SC_PDP_IN_EN in SYSREG */
		reg-names = "core", "common", "mux", "vc_mux", "en";
		interrupts = <0 INTREQ__PDP2 IRQ_TYPE_LEVEL_HIGH>,
			<0 INTREQ__PDP3 IRQ_TYPE_LEVEL_HIGH>;

		/*
		 * Select input CSIS link & VC
		 * <csi0 csi1 csi2 csi3 csi4 csi5 csi6>
		 */
		mux =  <0 1 2 3 4 5 6>;
		vc_mux = <0x2 0x2 0x2 0x2 0x2 0x2 0x2>, /* IMG: VC0, H_AF: VC2 */
		       <0x10003 0x10003 0x10003 0x10003 0x10003 0x10003 0x10003>; /* IMG: VC1, H_AF: VC3 */

		en =  <0 1 2 3 4 5 6>; /* bit postion: <csi0 csi1 csi2 csi3 csi4 csi5 csi6> */
		leader; /* have RDMA & create video node */
		lic_lut = <&lic_lut_origin>;
	};

	sensor_paf_pdp_2: sensor-paf-pdp@17120000 {
		/* PDP CORE2 */
		compatible = "samsung,sensor-paf-pdp";
		reg = <0x0 0x17120000 0x10000>, /* PDP CORE0 */
			<0x0 0x17100000 0x10000>, /* PDP CORE0: For common regiser */
			<0x0 0x17020518 0x4>, /* PDP input mux(CSIS_PDP_SC_CON0) in SYSREG */
			<0x0 0x17020438 0x4>, /* PDP input vc mux(CSIS_PDP_VC_CON0) in SYSREG */
			<0x0 0x17020538 0x4>; /* CSIS_PDP_SC_PDP_IN_EN in SYSREG */
		reg-names = "core", "common", "mux", "vc_mux", "en";
		interrupts = <0 INTREQ__PDP4 IRQ_TYPE_LEVEL_HIGH>,
			<0 INTREQ__PDP5 IRQ_TYPE_LEVEL_HIGH>;

		/*
		 * Select input CSIS link & VC
		 * <csi0 csi1 csi2 csi3 csi4 csi5 csi6>
		 */
		mux =  <0 1 2 3 4 5 6>;
		vc_mux = <0x2 0x2 0x2 0x2 0x2 0x2 0x2>, /* IMG: VC0, H_AF: VC2 */
		       <0x10003 0x10003 0x10003 0x10003 0x10003 0x10003 0x10003>; /* IMG: VC1, H_AF: VC3 */

		en =  <0 1 2 3 4 5 6>; /* bit postion: <csi0 csi1 csi2 csi3 csi4 csi5 csi6> */
		leader; /* have RDMA & create video node */
		lic_lut = <&lic_lut_origin>;
	};

	sensor_paf_pdp_3: sensor-paf-pdp@17130000 {
		/* PDP CORE3 */
		compatible = "samsung,sensor-paf-pdp";
		reg = <0x0 0x17130000 0x10000>, /* PDP CORE0 */
			<0x0 0x17100000 0x10000>, /* PDP CORE0: For common regiser */
			<0x0 0x1702051C 0x4>, /* PDP input mux(CSIS_PDP_SC_CON0) in SYSREG */
			<0x0 0x1702043C 0x4>, /* PDP input vc mux(CSIS_PDP_VC_CON0) in SYSREG */
			<0x0 0x1702053C 0x4>; /* CSIS_PDP_SC_PDP_IN_EN in SYSREG */
		reg-names = "core", "common", "mux", "vc_mux", "en";
		interrupts = <0 INTREQ__PDP6 IRQ_TYPE_LEVEL_HIGH>,
			<0 INTREQ__PDP7 IRQ_TYPE_LEVEL_HIGH>;

		/*
		 * Select input CSIS link & VC
		 * <csi0 csi1 csi2 csi3 csi4 csi5 csi6>
		 */
		mux =  <0 1 2 3 4 5 6>; /* <csi0 csi1 csi2 csi3 csi4 csi5 csi6> */
		vc_mux = <0x2 0x2 0x2 0x2 0x2 0x2 0x2>, /* IMG: VC0, H_AF: VC2 */
		       <0x10003 0x10003 0x10003 0x10003 0x10003 0x10003 0x10003>; /* IMG: VC1, H_AF: VC3 */

		en =  <0 1 2 3 4 5 6>; /* bit postion: <csi0 csi1 csi2 csi3 csi4 csi5 csi6> */
		leader; /* have RDMA & create video node */
		lic_lut = <&lic_lut_origin>;
	};

	aliases {
		pdp0 = &sensor_paf_pdp_0;
		pdp1 = &sensor_paf_pdp_1;
		pdp2 = &sensor_paf_pdp_2;
		pdp3 = &sensor_paf_pdp_3;
	};

	/*
	 * default setfiles for DPHY & CPHY
	 * <addr, bit_start, bit_width, val, index, max_lane>
	 */
	dphy_setfile: dphy-setfile@00 {
		comm {
			/* bias */
			0  = <0x1000 0 32 0x00000010 IDX_BIA_VAL 0>; /* M_BIAS_CON0 */
			1  = <0x1004 0 32 0x00000110 IDX_BIA_VAL 0>; /* M_BIAS_CON1 */
			2  = <0x1008 0 32 0x00003223 IDX_BIA_VAL 0>; /* M_BIAS_CON2 */
			3  = <0x1010 0 32 0x00000200 IDX_BIA_VAL 0>; /* M_BIAS_CON4 */
			4  = <0x1114 0 32 0x00000500 IDX_BIA_VAL 0>; /* M_PLL_CON5 */
			5  = <0x1118 0 32 0x0000008E IDX_BIA_VAL 0>; /* M_PLL_CON6 */
			6  = <0x111C 0 32 0x00003D40 IDX_BIA_VAL 0>; /* M_PLL_CON7 */
			7  = <0x1120 0 32 0x00001E00 IDX_BIA_VAL 0>; /* M_PLL_CON8 */
			8  = <0x1124 0 32 0x00001300 IDX_BIA_VAL 0>; /* M_PLL_CON9 */

			/* Clock lane */
			9  = <0x0004 0 32 0x00003D40 IDX_FIX_VAL 0>; /* SC_GNR_CON1 */
			10 = <0x0008 0 32 0x00000004 IDX_FIX_VAL 0>; /* SC_ANA_CON0 */
			11 = <0x000C 0 32 0x0000A0F0 IDX_FIX_VAL 0>; /* SC_ANA_CON1 */
			12 = <0x0010 0 32 0x00000002 IDX_FIX_VAL 0>; /* SC_ANA_CON2 */
			13 = <0x0014 0 32 0x00008600 IDX_FIX_VAL 0>; /* SC_ANA_CON3 */
			14 = <0x0018 0 32 0x00004000 IDX_FIX_VAL 0>; /* SC_ANA_CON4 */
			15 = <0x0030 0 32 0x00000309 IDX_FIX_VAL 0>; /* SC_TIME_CON0 */
			16 = <0x0040 0 32 0x00000001 IDX_FIX_VAL 0>; /* SC_DATA_CON0 */

			/* Enable should be set at last */
			17 = <0x0000 0 32 0x00000001 IDX_FIX_VAL 0>; /* SC_GNR_CON0 */
		};

		lane {
			0  = <0x0004 0 32 0x00003D40 IDX_FIX_VAL 4>; /* SD_GNR_CON1 */
			1  = <0x0008 0 32 0x00000004 IDX_FIX_VAL 4>; /* SD_ANA_CON0 */
			2  = <0x000C 0 32 0x0000A0F0 IDX_FIX_VAL 4>; /* SD_ANA_CON1 */
			3  = <0x0010 0 32 0x00000002 IDX_FIX_VAL 4>; /* SD_ANA_CON2 */
			4  = <0x0010 8  2 0x00000000 IDX_SKW_DLY 4>; /* SD_ANA_CON2 */
			5  = <0x0014 0 32 0x00008600 IDX_FIX_VAL 4>; /* SD_ANA_CON3 */
			6  = <0x0018 0 32 0x00002000 IDX_FIX_VAL 4>; /* SD_ANA_CON4 */
			7  = <0x0018 0 32 0x00004000 IDX_FIX_VAL 3>; /* SD_ANA_CON4 */

			8  = <0x0030 0  8 0x00000000 IDX_STL_VAL 4>; /* SD_TIME_CON0 */
			9  = <0x0030 8  1 0x00000000 IDX_STL_CLK 4>; /* SD_TIME_CON0 */
			10 = <0x0034 0 32 0x00000003 IDX_FIX_VAL 4>; /* SD_TIME_CON1 */
			11 = <0x0040 0  1 0x00000000 IDX_SKW_CAL 4>; /* SD_DESKEW_CON0 */
			12 = <0x0050 0 32 0x0000081A IDX_FIX_VAL 4>; /* SD_DESKEW_CON4 */

			/* Enable should be set at last */
			13 = <0x0000 0 32 0x00000001 IDX_FIX_VAL 4>;/* SD_GNR_CON0 */
		};
	};

	cphy_setfile: cphy-setfile@00 {
		comm {
		       /* bias */
		       0  = <0x1000 0 32 0x00000010 IDX_BIA_VAL 0>; /* M_BIAS_CON0 */
		       1  = <0x1004 0 32 0x00000110 IDX_BIA_VAL 0>; /* M_BIAS_CON1 */
		       2  = <0x1008 0 32 0x00003223 IDX_BIA_VAL 0>; /* M_BIAS_CON2 */
		       3  = <0x1010 0 32 0x00000240 IDX_BIA_VAL 0>; /* M_BIAS_CON4 */
		       4  = <0x1114 0 32 0x00000500 IDX_BIA_VAL 0>; /* M_PLL_CON5 */
		       5  = <0x1118 0 32 0x00000010 IDX_BIA_VAL 0>; /* M_PLL_CON6 */
		       6  = <0x111C 0 32 0x00003D40 IDX_BIA_VAL 0>; /* M_PLL_CON7 */
		       7  = <0x1120 0 32 0x00001E00 IDX_BIA_VAL 0>; /* M_PLL_CON8 */
		       8  = <0x1124 0 32 0x00001300 IDX_BIA_VAL 0>; /* M_PLL_CON9 */
		};

		lane {
			0  = <0x0004 0 32 0x00003D40 IDX_FIX_VAL 3>; /* SD_GNR_CON1 */
			1  = <0x0008 0 32 0x000000F7 IDX_FIX_VAL 3>; /* SD_ANA_CON0 */
			2  = <0x000C 0 32 0x0000FF29 IDX_FIX_VAL 3>; /* SD_ANA_CON1 */
			3  = <0x0010 0 32 0x00000005 IDX_FIX_VAL 3>; /* SD_ANA_CON2 */
			4  = <0x0014 0 32 0x00008600 IDX_FIX_VAL 3>; /* SD_ANA_CON3 */
			5  = <0x0018 0 32 0x00004040 IDX_FIX_VAL 3>; /* SD_ANA_CON4 */
			6  = <0x001C 0 32 0x00002200 IDX_FIX_VAL 3>; /* SD_ANA_CON5 */
			7  = <0x0020 0 32 0x00000E08 IDX_FIX_VAL 3>; /* SD_ANA_CON6 */
			8  = <0x0024 0 32 0x00000040 IDX_FIX_VAL 3>; /* SD_ANA_CON7 */
			9  = <0x0030 0  8 0x00000000 IDX_STL_VAL 3>; /* SD_TIME_CON0 */
			10 = <0x0030 8  1 0x00000000 IDX_STL_CLK 3>; /* SD_TIME_CON0 */
			11 = <0x0034 0 32 0x00000034 IDX_FIX_VAL 3>; /* SD_TIME_CON1 */
			12 = <0x005C 0 32 0x00001000 IDX_FIX_VAL 3>; /* SD_CRC_DLY_CON0 */
			13 = <0x0064 0 32 0x00001501 IDX_FIX_VAL 3>; /* SD_CRC_CON1 */
			14 = <0x0068 0 32 0x00000023 IDX_FIX_VAL 3>; /* SD_CRC_CON2 */
			15 = <0x009c 0 32 0x00000080 IDX_FIX_VAL 3>; /* SD_CRC_DLY_CON3 */

			/* Enable should be set at last */
			16 = <0x0000 0 32 0x00000001 IDX_FIX_VAL 3>; /* SD_GNR_CON0 */
		};
	};

	cphy_univ_2la_setfile: cphy-univ-2la-setfile@00 {
		comm {
		       /* bias */
		       0  = <0x1000 0 32 0x00000010 IDX_BIA_VAL 0>; /* M_BIAS_CON0 */
		       1  = <0x1004 0 32 0x00000110 IDX_BIA_VAL 0>; /* M_BIAS_CON1 */
		       2  = <0x1008 0 32 0x00003223 IDX_BIA_VAL 0>; /* M_BIAS_CON2 */
		       3  = <0x1010 0 32 0x00000240 IDX_BIA_VAL 0>; /* M_BIAS_CON4 */
		       4  = <0x1114 0 32 0x00000500 IDX_BIA_VAL 0>; /* M_PLL_CON5 */
		       5  = <0x1118 0 32 0x00000010 IDX_BIA_VAL 0>; /* M_PLL_CON6 */
		       6  = <0x111C 0 32 0x00003D40 IDX_BIA_VAL 0>; /* M_PLL_CON7 */
		       7  = <0x1120 0 32 0x00001E00 IDX_BIA_VAL 0>; /* M_PLL_CON8 */
		       8  = <0x1124 0 32 0x00001300 IDX_BIA_VAL 0>; /* M_PLL_CON9 */
		};

		lane {
			0  = <0x0004 0 32 0x00003D40 IDX_FIX_VAL 3>; /* SD_GNR_CON1 */
			1  = <0x0008 0 32 0x000000F7 IDX_FIX_VAL 3>; /* SD_ANA_CON0 */
			2  = <0x000C 0 32 0x0000FF29 IDX_FIX_VAL 3>; /* SD_ANA_CON1 */
			3  = <0x0010 0 32 0x00000005 IDX_FIX_VAL 3>; /* SD_ANA_CON2 */
			4  = <0x0014 0 32 0x00008600 IDX_FIX_VAL 3>; /* SD_ANA_CON3 */
			5  = <0x0018 0 32 0x00004040 IDX_FIX_VAL 3>; /* SD_ANA_CON4 */
			6  = <0x001C 0 32 0x00002200 IDX_FIX_VAL 3>; /* SD_ANA_CON5 */
			7  = <0x0020 0 32 0x00000E08 IDX_FIX_VAL 3>; /* SD_ANA_CON6 */
			8  = <0x0024 0 32 0x00000040 IDX_FIX_VAL 3>; /* SD_ANA_CON7 */
			9  = <0x0030 0  8 0x00000000 IDX_STL_VAL 3>; /* SD_TIME_CON0 */
			10 = <0x0030 8  1 0x00000000 IDX_STL_CLK 3>; /* SD_TIME_CON0 */
			11 = <0x0034 0 32 0x00000034 IDX_FIX_VAL 3>; /* SD_TIME_CON1 */
			12 = <0x005C 0 32 0x00001000 IDX_FIX_VAL 3>; /* SD_CRC_DLY_CON0 */
			13 = <0x0064 0 32 0x00001501 IDX_FIX_VAL 3>; /* SD_CRC_CON1 */
			14 = <0x0068 0 32 0x00000023 IDX_FIX_VAL 3>; /* SD_CRC_CON2 */
			15 = <0x009c 0 32 0x00000080 IDX_FIX_VAL 3>; /* SD_CRC_DLY_CON3 */

			/* Enable should be set at last */
			16 = <0x0000 0 32 0x00000001 IDX_FIX_VAL 3>; /* SD_GNR_CON0 */
		};
	};
};
